# STM32G030 register map
File version: 1.6
CPU: CM0 r0p1, little endian, MPU, no FPU, 2 interrupt priority bits
Registers are 32-bit, read-write, reset 0x0 unless marked. A register's access mark holds for its fields unless they carry their own. Offsets are from the block's base; lines under a group give offsets from that group; [hi:lo] are bit positions; {n}, {i} and the like mark numbered series; 'fields as' and 'values as' point back to an identical list; <NAME> marks a mode.

## Memory map
0x40000400 TIM3 size 0x400 — General-purpose-timers
0x40002000 TIM14 size 0x400 — General purpose timers
0x40002800 RTC size 0x400 — Real-time clock
0x40002C00 WWDG size 0x400 — System window watchdog
0x40003000 IWDG size 0x400 — Independent watchdog
0x40003800 SPI2 size 0x400
0x40004400 USART2 size 0x400
0x40005400 I2C1 size 0x400 — Inter-integrated circuit
0x40005800 I2C2 size 0x400
0x40007000 PWR size 0x400 — Power control
0x4000B000 TAMP size 0x400 — Tamper and backup registers
0x40010000 SYSCFG size 0x100 — System configuration controller
0x40010030 VREFBUF size 0x50 — System configuration controller
0x40012400 ADC size 0x400 — Analog to Digital ConverteR
0x40012C00 TIM1 size 0x400 — Advanced-timers
0x40013000 SPI1 size 0x400 — Serial peripheral interface/Inter-IC sound
0x40013800 USART1 size 0x400 — Universal synchronous asynchronous receiver transmitter
0x40014400 TIM16 size 0x400 — General purpose timers
0x40014800 TIM17 size 0x400
0x40015800 DBG size 0x400 — MCU debug component
0x40020000 DMA1 size 0x400 — DMA controller
0x40020800 DMAMUX size 0x400
0x40021000 RCC size 0x400 — Reset and clock control
0x40021800 EXTI size 0x400 — External interrupt/event controller
0x40022000 FLASH size 0x400
0x40023000 CRC size 0x400 — Cyclic redundancy check calculation unit
0x50000000 GPIOA size 0x400 — General-purpose I/Os
0x50000400 GPIOB size 0x400 — General-purpose I/Os
0x50000800 GPIOC size 0x400
0x50000C00 GPIOD size 0x400
0x50001400 GPIOF size 0x400

## Interrupts
0 WWDG — Window watchdog interrupt
2 RTC_STAMP (RTC) — RTC and TAMP interrupts
3 FLASH — Flash global interrupt
4 RCC — RCC global interrupt
5 EXTI0_1 (EXTI) — EXTI line 0 and 1 interrupt
6 EXTI2_3 (EXTI) — EXTI line 2 and 3 interrupt
7 EXTI4_15 (EXTI) — EXTI line 4 to 15 interrupt
9 DMA1_Channel1 (DMA1) — DMA channel 1 interrupt
10 DMA1_Channel2_3 (DMA1) — DMA channel 2 and 3 interrupts
11 DMA1_Channel4_5_DMAMUX (DMA1) — interrupts for DMA1 channels 4-5 and DMAMUX
12 ADC — ADC interrupt (ADC combined with EXTI 17 and 18)
13 TIM1_BRK_UP_TRG_COM (TIM1) — TIM1 break, update, trigger
14 TIM1_CC (TIM1) — TIM1 Capture Compare interrupt
16 TIM3 — TIM3 global interrupt
19 TIM14 — TIM14 global interrupt
21 TIM16 — TIM16 global interrupt
22 TIM17 — TIM17 global interrupt
23 I2C1 — I2C1 global interrupt
24 I2C2 — I2C2 global interrupt
25 SPI1 — SPI1 global interrupt
26 SPI2 — SPI2 global interrupt
27 USART1 — USART1 global interrupt
28 USART2 — USART2 global interrupt
30 CEC (CRC) — CEC global interrupt

## IWDG — Independent watchdog
Base 0x40003000
0x00 KR 16-bit wo — Key register
  [15:0] KEY — Key value (write only, read 0x0000)
    0x5555=Unlock (Enable access to PR, RLR and WINR registers); 0xAAAA=Feed watchdog with RLR register value; 0xCCCC=Start the watchdog
0x04 PR 16-bit — Prescaler register
  [2:0] PR — Prescaler divider
    0=DivideBy4 (Divider /4); 1=DivideBy8 (Divider /8); 2=DivideBy16 (Divider /16); 3=DivideBy32 (Divider /32); 4=DivideBy64 (Divider /64); 5=DivideBy128 (Divider /128); other=DivideBy256 (Divider /256)
0x08 RLR 16-bit reset 0xFFF — Reload register
  [11:0] RL — Watchdog counter reload value
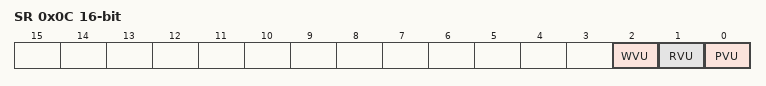
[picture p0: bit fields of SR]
0x0C SR 16-bit ro — Status register
  [2] WVU — Watchdog counter window value update
  [1] RVU — Watchdog counter reload value update
  [0] PVU — Watchdog prescaler value update
0x10 WINR 16-bit reset 0xFFF — Window register
  [11:0] WIN — Watchdog counter window value

## WWDG — System window watchdog
Base 0x40002C00
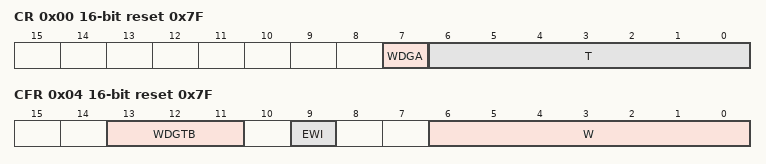
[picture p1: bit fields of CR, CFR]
0x00 CR 16-bit reset 0x7F — Control register
  [7] WDGA — Activation bit
    0=Disabled (Watchdog disabled); 1=Enabled (Watchdog enabled)
  [6:0] T — 7-bit counter (MSB to LSB)
0x04 CFR 16-bit reset 0x7F — Configuration register
  [13:11] WDGTB — Timer base
    0=Div1 (Counter clock (PCLK1 div 4096) div 1); 1=Div2 (Counter clock (PCLK1 div 4096) div 2); 2=Div4 (Counter clock (PCLK1 div 4096) div 4); 3=Div8 (Counter clock (PCLK1 div 4096) div 8); 4=Div16 (Counter clock (PCLK1 div 4096) div 16); 5=Div32 (Counter clock (PCLK1 div 4096) div 32); 6=Div64 (Counter clock (PCLK1 div 4096) div 64); 7=Div128 (Counter clock (PCLK1 div 4096) div 128)
  [9] EWI — Early wakeup interrupt
    on write: 1=Enable (interrupt occurs whenever the counter reaches the value 0x40)
  [6:0] W — 7-bit window value
0x08 SR 16-bit — Status register
  [0] EWIF write-0-clears — Early wakeup interrupt flag
    on read: 0=Finished (The EWI Interrupt Service Routine has been serviced); 1=Pending (The EWI Interrupt Service Routine has been triggered) | on write: 0=Finished (The EWI Interrupt Service Routine has been serviced)
